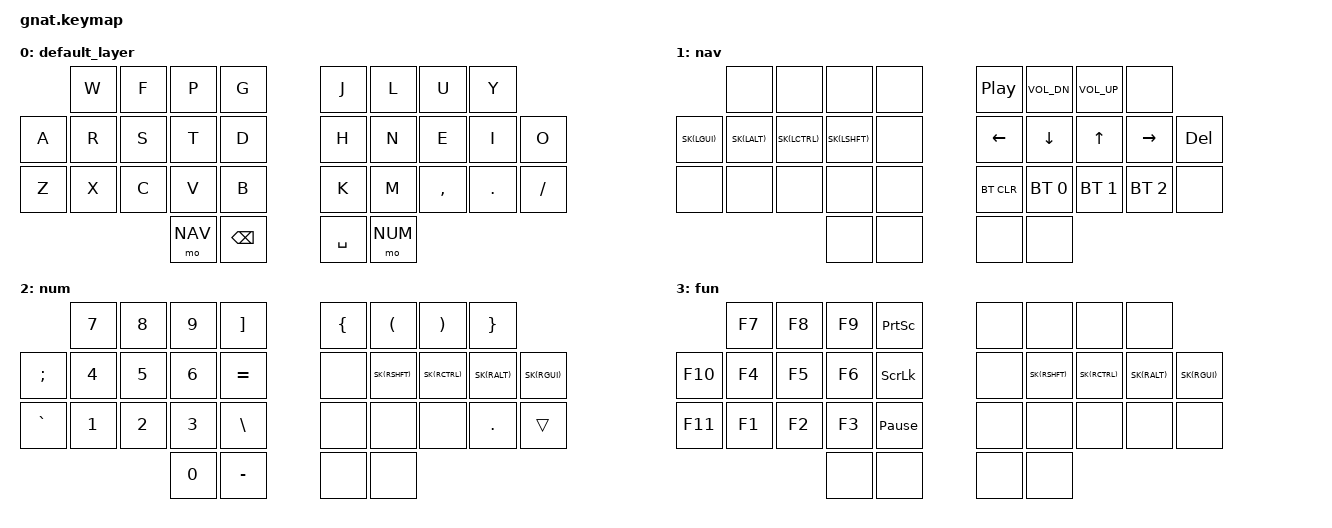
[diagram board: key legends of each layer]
/*
 * Copyright (c) 2020 The ZMK Contributors
 *
 * SPDX-License-Identifier: MIT
 */

#include <behaviors.dtsi>
#include <dt-bindings/zmk/keys.h>
#include <dt-bindings/zmk/bt.h>

#define             BASE    0
#define             NAV     1
#define             NUM     2
#define             FUN     3

#define VOL_U       &kp C_VOL_UP
#define VOL_D       &kp C_VOL_DN
#define PB          &kp PAUSE_BREAK

#define BTCLR       &bt BT_CLR
#define BT0         &bt BT_SEL 0
#define BT1         &bt BT_SEL 1
#define BT2         &bt BT_SEL 2
#define BT3         &bt BT_SEL 3

#define SK(KEY)     &nk KEY KEY

&kscan0 {
    debounce-period  = <12>;
};

&sk {
    quick-release;
};

&caps_word {
    continue-list = <UNDERSCORE MINUS BACKSPACE>;
};

/ {
        combos {
            compatible = "zmk,combos";

            combo_q {
                timeout-ms = <30>;
                key-positions = <19 20>;
                bindings = <&kp Q>;
                layers = <BASE>;
            };

            combo_q_top {
                timeout-ms = <30>;
                key-positions = <0 1>;
                bindings = <&kp Q>;
                layers = <BASE>;
            };

            combo_sqt {
                timeout-ms = <30>;
                key-positions = <25 26>;
                bindings = <&kp SQT>;
                layers = <BASE>;
            };

            combo_sqt_top {
                timeout-ms = <30>;
                key-positions = <6 7>;
                bindings = <&kp SQT>;
                layers = <BASE>;
            };

            combo_esc {
                timeout-ms = <30>;
                key-positions = <9 10>;
                bindings = <&kp ESC>;
                layers = <NUM>;
            };

            combo_tab {
                timeout-ms = <30>;
                key-positions = <11 21>;
                bindings = <&kp TAB>;
                layers = <BASE>;
            };

            combo_ret {
                timeout-ms = <30>;
                key-positions = <14 24>;
                bindings = <&kp RET>;
                layers = <BASE>;
            };

            combo_caps_word {
                timeout-ms = <50>;
                key-positions = <3 12>;
                bindings = <&caps_word>;
                layers = <NUM>;
            };

            combo_lbkt {
                timeout-ms = <30>;
                key-positions = <0 1>;
                bindings = <&kp LBKT>;
                layers = <NUM>;
            };

            combo_f12 {
                timeout-ms = <30>;
                key-positions = <19 20>;
                bindings = <&kp F12>;
                layers = <FUN>;
            };

            // layer combos
            combo_fun {
                timeout-ms = <50>;
                key-positions = <28 31>;
                bindings = <&mo FUN>;
                layers = <BASE>;
            };
        };

        behaviors {

            // https://github.com/dxmh/zmk-config
            // Sticky key on tap, normal key on hold
            // Useful for modifier-clicking without the modifier remaining active
            nk: not_so_sticky_key {
                compatible = "zmk,behavior-hold-tap";
                label = "NOT_SO_STICKY_KEY";
                #binding-cells = <2>;
                tapping_term_ms = <200>;
                flavor = "tap-preferred";
                bindings = <&kp>, <&sk>;
            };

        };

        keymap {
            compatible = "zmk,keymap";

            default_layer {
        bindings = <
                        &kp W       &kp F       &kp P       &kp G       /**/ /**/       &kp J       &kp L       &kp U       &kp Y
            &kp A       &kp R       &kp S       &kp T       &kp D       /**/ /**/       &kp H       &kp N       &kp E       &kp I       &kp O
            &kp Z       &kp X       &kp C       &kp V       &kp B       /**/ /**/       &kp K       &kp M       &kp COMMA   &kp DOT     &kp SLASH
                                                &mo NAV     &kp BSPC                    &kp SPC     &mo NUM
        >;
        };

            nav {
        bindings = <
                        &none       &none       &none       &none       /**/ /**/       &kp C_PP    VOL_D       VOL_U       &none
            SK(LGUI)    SK(LALT)    SK(LCTRL)   SK(LSHFT)   &none       /**/ /**/       &kp LEFT    &kp DOWN    &kp UP      &kp RIGHT   &kp DEL
            &none       &none       &none       &none       &none       /**/ /**/       BTCLR       BT0         BT1         BT2         &none
                                                &none       &none                       &none       &none
        >;
        };
            num {
        bindings = <
                        &kp N7      &kp N8      &kp N9      &kp RBKT    /**/ /**/       &kp LBRC    &kp LPAR    &kp RPAR    &kp RBRC
            &kp SEMI    &kp N4      &kp N5      &kp N6      &kp EQUAL   /**/ /**/       &none       SK(RSHFT)   SK(RCTRL)   SK(RALT)    SK(RGUI)
            &kp GRAVE   &kp N1      &kp N2      &kp N3      &kp BSLH    /**/ /**/       &none       &none       &none       &kp DOT     &trans
                                                &kp N0      &kp MINUS                   &none       &none
        >;
        };

            fun {
        bindings = <
                        &kp F7      &kp F8      &kp F9      &kp PSCRN   /**/ /**/       &none       &none       &none       &none
            &kp F10     &kp F4      &kp F5      &kp F6      &kp SLCK    /**/ /**/       &none       SK(RSHFT)   SK(RCTRL)   SK(RALT)    SK(RGUI)
            &kp F11     &kp F1      &kp F2      &kp F3      PB          /**/ /**/       &none       &none       &none       &none       &none
                                                &none       &none                       &none       &none
        >;
        };

    };
};
